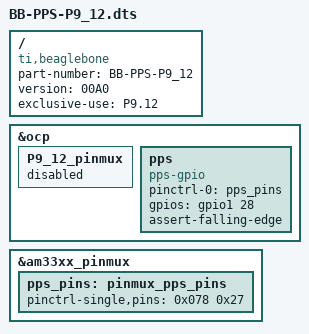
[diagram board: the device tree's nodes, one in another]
/*
 *
 */
/dts-v1/;
/plugin/;

/ {
	compatible = "ti,beaglebone", "ti,beaglebone-black";

	/* identification */
	part-number = "BB-PPS-P9_12";
	version = "00A0";
	
	/* state the resources this cape uses */
	exclusive-use =
	/* the pin header uses */
	"P9.12";	/* pps gpio */

	/*
	 * Free up the pins used by the cape from the pinmux helpers.
	 */
	fragment@0 {
		target = <&ocp>;
		__overlay__ {
			P9_12_pinmux { status = "disabled"; }; 
		};
	};

	fragment@1 {
		target = <&am33xx_pinmux>;
		__overlay__ {
			pps_pins: pinmux_pps_pins {
				pinctrl-single,pins = <
					0x078	0x27	/* gpmc_a0.gpio1_28, INPUT | PULLDIS | MODE7 */
				>;
			};
		};
	};

	fragment@2 {
		target = <&ocp>;
		__overlay__ {
			pps {
				compatible = "pps-gpio";
				status = "okay";
				pinctrl-names = "default";
				pinctrl-0 = <&pps_pins>;

				gpios = <&gpio1 28 0>; /*really gpio1!*/
				assert-falling-edge;
			};
		};
	};
};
